# MIMXRT1061 register map
Vendor: nxp.com; File version: 1.0
CPU: CM7 r0p1, little endian, MPU, FPU, VTOR, 4 interrupt priority bits
Registers are 32-bit, read-write, reset 0x0 unless marked. A register's access mark holds for its fields unless they carry their own. Offsets are from the block's base; [hi:lo] are bit positions; 'fields as' and 'values as' point back to an identical list.

## RTWDOG — WDOG
Base 0x400BC000
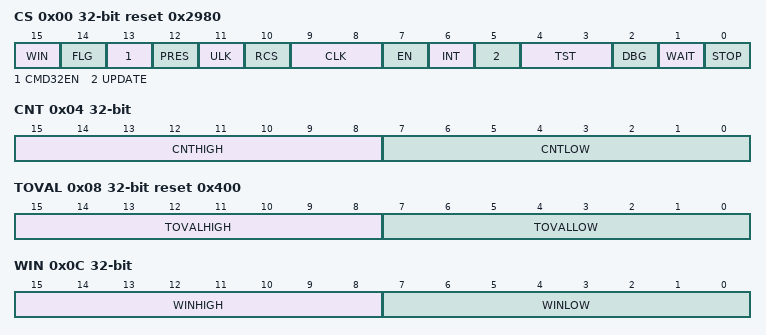
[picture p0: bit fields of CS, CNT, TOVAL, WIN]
0x00 CS reset 0x2980 — Watchdog Control and Status Register
  [15] WIN — Watchdog Window
    0=DIS (Window mode disabled.); 1=EN (Window mode enabled.)
  [14] FLG write-1-clears — Watchdog Interrupt Flag
    0=NO (No interrupt occurred.); 1=YES (An interrupt occurred.)
  [13] CMD32EN — Enables or disables WDOG support for 32-bit (otherwise 16-bit or 8-bit) refresh/unlock command write words
    0=DIS (Disables support for 32-bit refresh/unlock command write words. Only 16-bit or 8-bit is supported.); 1=EN (Enables support for 32-bit refresh/unlock command write words. 16-bit or 8-bit is NOT supported.)
  [12] PRES — Watchdog prescaler
    0=DIS (256 prescaler disabled.); 1=EN (256 prescaler enabled.)
  [11] ULK ro — Unlock status
    0=LOCK (WDOG is locked.); 1=UNLOCK (WDOG is unlocked.)
  [10] RCS ro — Reconfiguration Success
    0=RECONFIG (Reconfiguring WDOG.); 1=SUCCESS (Reconfiguration is successful.)
  [9:8] CLK — Watchdog Clock
  [7] EN — Watchdog Enable
    0=DIS (Watchdog disabled.); 1=EN (Watchdog enabled.)
  [6] INT — Watchdog Interrupt
    0=DIS (Watchdog interrupts are disabled. Watchdog resets are not delayed.); 1=EN (Watchdog interrupts are enabled. Watchdog resets are delayed by 128 bus clocks from the interrupt vector fetch.)
  [5] UPDATE — Allow updates
    0=DIS (Updates not allowed. After the initial configuration, the watchdog cannot be later modified without forcing a reset.); 1=EN (Updates allowed. Software can modify the watchdog configuration registers within 128 bus clocks after performing the unlock write sequence.)
  [4:3] TST — Watchdog Test
    0=DIS (Watchdog test mode disabled.); 1=EN (Watchdog user mode enabled. (Watchdog test mode disabled.) After testing the watchdog, software should use this setting to indicate that the watchdog is functioning normally in user mode.); 2=EN_LOW (Watchdog test mode enabled, only the low byte is used. CNT[CNTLOW] is compared with TOVAL[TOVALLOW].); 3=EN_HIGH (Watchdog test mode enabled, only the high byte is used. CNT[CNTHIGH] is compared with TOVAL[TOVALHIGH].)
  [2] DBG — Debug Enable
    0=DIS (Watchdog disabled in chip debug mode.); 1=EN (Watchdog enabled in chip debug mode.)
  [1] WAIT — Wait Enable
    0=DIS (Watchdog disabled in chip wait mode.); 1=EN (Watchdog enabled in chip wait mode.)
  [0] STOP — Stop Enable
    0=DIS (Watchdog disabled in chip stop mode.); 1=EN (Watchdog enabled in chip stop mode.)
0x04 CNT — Watchdog Counter Register
  [15:8] CNTHIGH — High byte of the Watchdog Counter
  [7:0] CNTLOW — Low byte of the Watchdog Counter
0x08 TOVAL reset 0x400 — Watchdog Timeout Value Register
  [15:8] TOVALHIGH — High byte of the timeout value
  [7:0] TOVALLOW — Low byte of the timeout value
0x0C WIN — Watchdog Window Register
  [15:8] WINHIGH — High byte of Watchdog Window
  [7:0] WINLOW — Low byte of Watchdog Window

## TEMPMON — Temperature Monitor
Base 0x400D8000; register names take the prefix TEMPMON_; alternate view of CCM_ANALOG
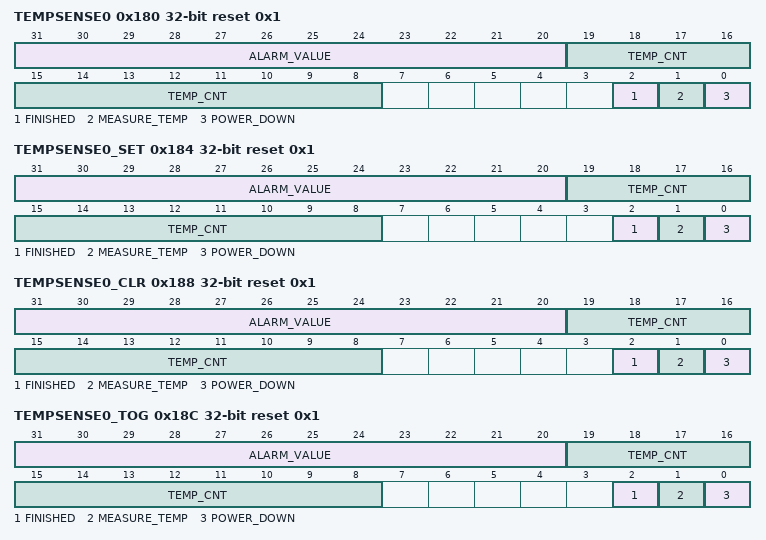
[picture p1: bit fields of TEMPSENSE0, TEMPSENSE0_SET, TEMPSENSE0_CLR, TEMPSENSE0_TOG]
0x180 TEMPSENSE0 reset 0x1 — Tempsensor Control Register 0
  [31:20] ALARM_VALUE — This bit field contains the temperature count (raw sensor output) that will generate a high alarm when TEMP_CNT is smaller than this field
  [19:8] TEMP_CNT ro — This bit field contains the last measured temperature count.
  [2] FINISHED ro — Indicates that the latest temp is valid
    0=INVALID (Last measurement is not ready yet.); 1=VALID (Last measurement is valid.)
  [1] MEASURE_TEMP — Starts the measurement process
    0=STOP (Do not start the measurement process.); 1=START (Start the measurement process.)
  [0] POWER_DOWN — This bit powers down the temperature sensor.
    0=POWER_UP (Enable power to the temperature sensor.); 1=POWER_DOWN (Power down the temperature sensor.)
0x184 TEMPSENSE0_SET reset 0x1 — Tempsensor Control Register 0
  fields as TEMPSENSE0
0x188 TEMPSENSE0_CLR reset 0x1 — Tempsensor Control Register 0
  fields as TEMPSENSE0
0x18C TEMPSENSE0_TOG reset 0x1 — Tempsensor Control Register 0
  fields as TEMPSENSE0
0x190 TEMPSENSE1 reset 0x1 — Tempsensor Control Register 1
  [15:0] MEASURE_FREQ — This bits determines how many RTC clocks to wait before automatically repeating a temperature measurement
    0=Defines a single measurement with no repeat; 1=Updates the temperature value at a RTC clock rate; 2=Updates the temperature value at a RTC/2 clock rate; 0xFFFF=Determines a two second sample period with a 32.768KHz RTC clock. Exact timings depend on the accuracy of the RTC clock.
0x194 TEMPSENSE1_SET reset 0x1 — Tempsensor Control Register 1
  fields as TEMPSENSE1
0x198 TEMPSENSE1_CLR reset 0x1 — Tempsensor Control Register 1
  fields as TEMPSENSE1
0x19C TEMPSENSE1_TOG reset 0x1 — Tempsensor Control Register 1
  fields as TEMPSENSE1
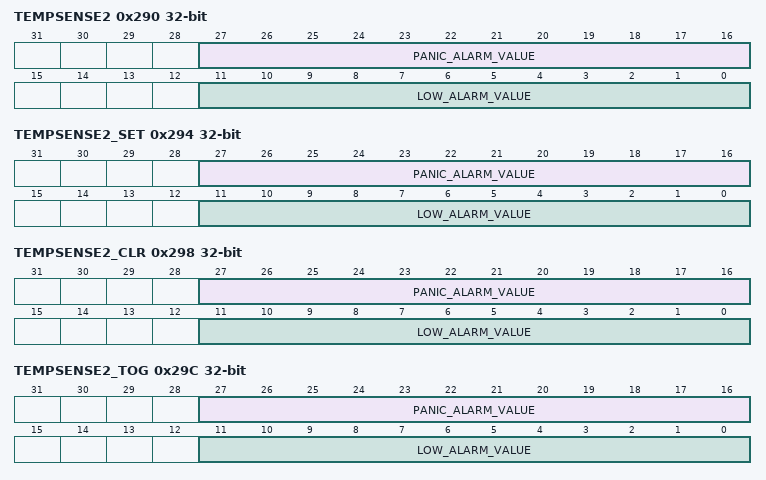
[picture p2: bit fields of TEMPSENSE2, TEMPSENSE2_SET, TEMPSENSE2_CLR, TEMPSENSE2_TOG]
0x290 TEMPSENSE2 — Tempsensor Control Register 2
  [27:16] PANIC_ALARM_VALUE — This bit field contains the temperature count that will generate a panic interrupt when TEMP_CNT is smaller than this field
  [11:0] LOW_ALARM_VALUE — This bit field contains the temperature count that will generate a low alarm interrupt when the field is exceeded by TEMP_CNT
0x294 TEMPSENSE2_SET — Tempsensor Control Register 2
  fields as TEMPSENSE2
0x298 TEMPSENSE2_CLR — Tempsensor Control Register 2
  fields as TEMPSENSE2
0x29C TEMPSENSE2_TOG — Tempsensor Control Register 2
  fields as TEMPSENSE2

## Notices in the file
Copyright 2016-2022 NXP
All rights reserved.
SPDX-License-Identifier: BSD-3-Clause
